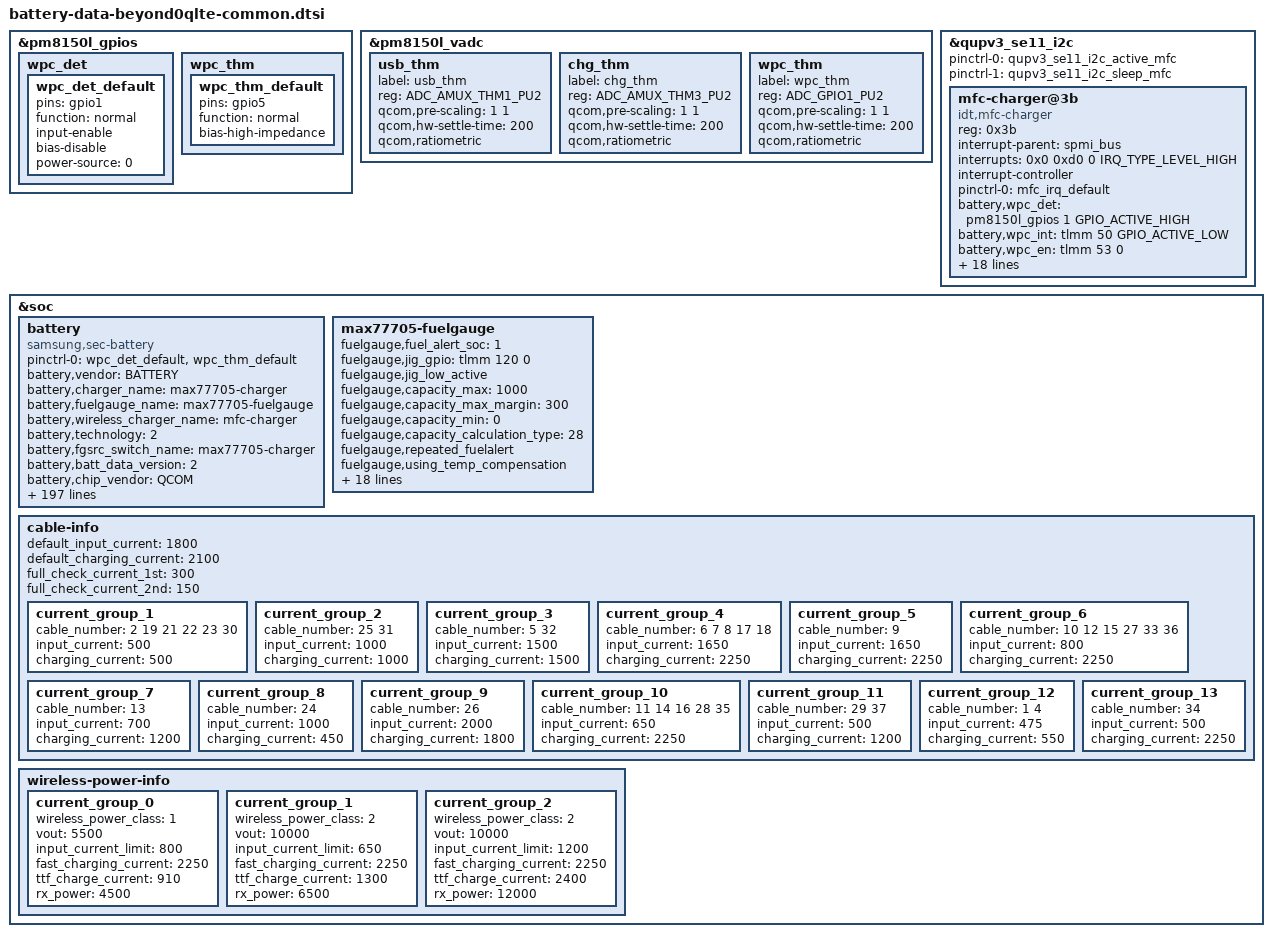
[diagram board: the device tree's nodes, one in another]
/* Copyright (c) 2014, The Linux Foundation. All rights reserved.
 *
 * This program is free software; you can redistribute it and/or modify
 * it under the terms of the GNU General Public License version 2 and
 * only version 2 as published by the Free Software Foundation.
 *
 * This program is distributed in the hope that it will be useful,
 * but WITHOUT ANY WARRANTY; without even the implied warranty of
 * MERCHANTABILITY or FITNESS FOR A PARTICULAR PURPOSE.  See the
 * GNU General Public License for more details.
 */

&pm8150l_gpios {
	wpc_det { /* WPC_DET */
		wpc_det_default: wpc_det_default {
			pins = "gpio1";
			function = "normal";
			input-enable;
			bias-disable;
			power-source = <0>;
		};
	};
	wpc_thm { /* GPIO_05 */
		wpc_thm_default: wpc_thm_default {
			pins = "gpio5";
			function = "normal";
			bias-high-impedance;
		};
	};
};

&pm8150l_vadc {
	usb_thm { /* AMUX_1 */
		label = "usb_thm";
		reg = <ADC_AMUX_THM1_PU2>;
		qcom,pre-scaling = <1 1>;
		qcom,hw-settle-time = <200>;
		qcom,ratiometric;
	};
	chg_thm { /* AMUX_3 */
		label = "chg_thm";
		reg = <ADC_AMUX_THM3_PU2>;
		qcom,pre-scaling = <1 1>;
		qcom,hw-settle-time = <200>;
		qcom,ratiometric;
	};
	wpc_thm { /* GPIO_05 */
		label = "wpc_thm";
		reg = <ADC_GPIO1_PU2>;
		qcom,pre-scaling = <1 1>;
		qcom,hw-settle-time = <200>;
		qcom,ratiometric;
	};
};

&qupv3_se11_i2c {
	status = "ok";

	pinctrl-0 = <&qupv3_se11_i2c_active_mfc>;
	pinctrl-1 = <&qupv3_se11_i2c_sleep_mfc>;

	mfc-charger@3b {
		compatible = "idt,mfc-charger";
		reg = <0x3b>;
		status = "okay";

		interrupt-parent = <&spmi_bus>;
		interrupts = <0x0 0xd0 0 IRQ_TYPE_LEVEL_HIGH>;
		interrupt-names = "default";
		interrupt-controller;
		pinctrl-names = "default";
		pinctrl-0 = <&mfc_irq_default>;
		battery,wpc_det = <&pm8150l_gpios 1 GPIO_ACTIVE_HIGH>; /* WPC_DET */
		battery,wpc_int = <&tlmm 50 GPIO_ACTIVE_LOW>; /* MFC_AP_INT */
		battery,wpc_en = <&tlmm 53 0>; /* WPC_EN */
		battery,mst_en = <&tlmm 11 0>; /* MST_EN */
		battery,mst_pwr_en = <&tlmm 60 0>; /* MST_PWR_EN */

		battery,charger_name = "max77705-charger";
		battery,fuelgauge_name = "max77705-fuelgauge";
		battery,wireless_charger_name = "mfc-charger";
		battery,fod_data = <150 57 142 48 150 33 150 27 165 237 156 13>;
		battery,fod_data_cv = <150 87 142 78 150 63 150 57 165 12 156 43>;
		battery,fod_hero_5v_data = <150 (-27) 142 (-37) 150 (-53) 150 (-53) 165 160 156 (-61)>;
		battery,wc_cover_rpp = <0x44>;
		battery,oc_fod1 = <1100>;
		battery,tx_gear_min_op_freq_delay = <4000>;
		battery,phone_fod_threshold = <0x3b>;		
		battery,wireless20_vout_list = <8>; /* WIRELESS_VOUT_10V*/
		battery,wireless20_vrect_list = <10>; /* MFC_AFC_CONF_12V_TX*/
		battery,wireless20_max_power_list = <2>; /* SEC_WIRELESS_RX_POWER_12W*/
	};
};

&soc {
	battery {
		status = "okay";
		compatible = "samsung,sec-battery";
		pinctrl-names = "default";
		pinctrl-0 = <&wpc_det_default &wpc_thm_default>;
		battery,vendor = "BATTERY";
		battery,charger_name = "max77705-charger";
		battery,fuelgauge_name = "max77705-fuelgauge";
		battery,wireless_charger_name = "mfc-charger";
		battery,technology = <2>; /* POWER_SUPPLY_TECHNOLOGY_LION */
		battery,fgsrc_switch_name = "max77705-charger"; /* Fuelgauge voltage source */

		battery,batt_data_version = <2>;

		battery,chip_vendor = "QCOM";
		battery,temp_adc_type = <1>; /* SEC_BATTERY_ADC_TYPE_AP */

		battery,temp_check_type = <1>; /* SEC_BATTERY_TEMP_CHECK_ADC */
		battery,usb_temp_check_type = <1>;
		battery,chg_temp_check_type = <1>;
		battery,wpc_temp_check_type = <1>;

		battery,thermal_source = <2>; /* SEC_BATTERY_THERMAL_SOURCE_ADC */
		battery,usb_thermal_source = <2>; /* SEC_BATTERY_THERMAL_SOURCE_ADC */
		battery,chg_thermal_source = <2>; /* SEC_BATTERY_THERMAL_SOURCE_ADC */
		battery,wpc_thermal_source = <2>; /* SEC_BATTERY_THERMAL_SOURCE_ADC */

		battery,polling_time = <10 30 30 30 3600>;

		battery,temp_table_adc = <146452 171453 197469 227486 264402
						306877 355795 413408 478330 553546
						633390 725216 825583 931271 1041716
						1153113 1259536 1360163 1455557 1535856
						1605990 1667106 1717884>;
		battery,temp_table_data = <900 850 800 750 700
						650 600 550 500 450
						400 350 300 250 200
						150 100 50 0 (-50)
						(-100) (-150) (-200)>;

		battery,usb_temp_table_adc = <133671 155600 181725 212391 250323
						291349 341327 399610 465765 541803
						622923 716046 818382 925972 1037586
						1150691 1258780 1360056 1456920 1537435
						1607871 1669398 1720523>;
		battery,usb_temp_table_data = <900 850 800 750 700
						650 600 550 500 450
						400 350 300 250 200
						150 100 50 0 (-50)
						(-100) (-150) (-200)>;

		battery,chg_temp_table_adc = <118901 149458 175778 205968 242754
						284364 334601 392538 458022 532655
						614403 706725 806465 913170 1022187
						1133801 1238927 1338732 1431833 1511202
						1579173 1640484 1699264>;
		battery,chg_temp_table_data = <900 850 800 750 700
						650 600 550 500 450
						400 350 300 250 200
						150 100 50 0 (-50)
						(-100) (-150) (-200)>;

		battery,wpc_temp_table_adc = <146452 171453 197469 227486 264402
						306877 355795 413408 478330 553546
						633390 725216 825583 931271 1041716
						1153113 1259536 1360163 1455557 1535856
						1605990 1667106 1717884>;
		battery,wpc_temp_table_data = <900 850 800 750 700
						650 600 550 500 450
						400 350 300 250 200
						150 100 50 0 (-50)
						(-100) (-150) (-200)>;

		battery,wireless_cc_cv = <85>;
		battery,wpc_det = <&pm8150l_gpios 1 GPIO_ACTIVE_HIGH>; /* WPC_DET */
		battery,wpc_en = <&tlmm 53 0>; /* WPC_EN */
		battery,mst_pwr_en = <&tlmm 60 0>; /* MST_PWR_EN */
		battery,adc_check_count = <5>;

		battery,cable_check_type = <4>; /* SEC_BATTERY_CABLE_CHECK_PSY */
		battery,cable_source_type = <1>; /* SEC_BATTERY_CABLE_SOURCE_EXTERNAL */
		battery,polling_type = <1>; /* SEC_BATTERY_MONITOR_ALARM */
		battery,monitor_initial_count = <0>;

		battery,battery_check_type = <0>; /* SEC_BATTERY_CHECK_NONE */
		battery,check_count = <0>;
		battery,check_adc_max = <1440>;
		battery,check_adc_min = <0>;

		battery,ovp_uvlo_check_type = <3>; /* SEC_BATTERY_OVP_UVLO_CHGPOLLING */

		battery,temp_check_count = <1>;
		battery,temp_highlimit_threshold_event = <700>;
		battery,temp_highlimit_recovery_event = <680>;
		battery,temp_high_threshold_event = <500>;
		battery,temp_high_recovery_event = <480>;
		battery,temp_low_threshold_event = <0>;
		battery,temp_low_recovery_event = <20>;
		battery,temp_highlimit_threshold_normal = <700>;
		battery,temp_highlimit_recovery_normal = <680>;
		battery,temp_high_threshold_normal = <500>;
		battery,temp_high_recovery_normal = <480>;
		battery,temp_low_threshold_normal = <0>;
		battery,temp_low_recovery_normal = <20>;
		battery,temp_highlimit_threshold_lpm = <700>;
		battery,temp_highlimit_recovery_lpm = <680>;
		battery,temp_high_threshold_lpm = <500>;
		battery,temp_high_recovery_lpm = <480>;
		battery,temp_low_threshold_lpm = <0>;
		battery,temp_low_recovery_lpm = <20>;
		battery,wpc_high_threshold_normal = <450>;
		battery,wpc_high_recovery_normal = <430>;
		battery,wpc_low_threshold_normal = <0>;
		battery,wpc_low_recovery_normal = <20>;
		battery,tx_high_threshold = <450>;
		battery,tx_high_recovery = <400>;
		battery,tx_low_threshold = <0>;
		battery,tx_low_recovery = <50>;
		battery,full_check_type = <7>; /* SEC_BATTERY_FULLCHARGED_CHGPSY */
		battery,full_check_type_2nd = <7>; /* SEC_BATTERY_FULLCHARGED_CHGPSY */
		battery,full_check_count = <1>;
		battery,chg_gpio_full_check = <0>;
		battery,chg_polarity_full_check = <1>;

		battery,chg_high_temp = <460>;
		battery,chg_high_temp_recovery = <440>;
		battery,chg_input_limit_current = <1000>;
		battery,chg_charging_limit_current = <1250>;

		battery,wpc_temp_control_source = <1>; /* TEMP_CONTROL_SOURCE_BAT_THM = WPC_THM */
		battery,wpc_high_temp = <380>;
		battery,wpc_high_temp_recovery = <360>;
		battery,wpc_input_limit_current = <600>;
		battery,wpc_charging_limit_current = <1000>;
		battery,wpc_temp_lcd_on_control_source = <1>; /* TEMP_CONTROL_SOURCE_BAT_THM = WPC_THM */
		battery,wpc_lcd_on_high_temp = <380>;
		battery,wpc_lcd_on_high_temp_rec = <360>;
		battery,wpc_lcd_on_input_limit_current = <450>;

		battery,wpc_store_high_temp = <360>;
		battery,wpc_store_high_temp_recovery = <340>;
		battery,wpc_store_charging_limit_current = <400>;
		battery,wpc_store_lcd_on_high_temp = <360>;
		battery,wpc_store_lcd_on_high_temp_rec = <300>;
		battery,wpc_store_lcd_on_charging_limit_current = <400>;

		battery,sleep_mode_limit_current = <800>;
		battery,wc_full_input_limit_current = <100>;

		battery,mix_high_temp = <420>;
		battery,mix_high_chg_temp = <500>;
		battery,mix_high_temp_recovery = <390>;

		/* SEC_BATTERY_FULL_CONDITION_NOTIMEFULL | SEC_BATTERY_FULL_CONDITION_VCELL */
		battery,full_condition_type = <9>;
		battery,full_condition_soc = <93>;
		battery,full_condition_vcell = <4250>;

		battery,recharge_check_count = <1>;
		battery,recharge_condition_type = <4>; /* SEC_BATTERY_RECHARGE_CONDITION_VCELL */
		battery,recharge_condition_soc = <98>;
		battery,recharge_condition_vcell = <4280>;

		battery,charging_total_time = <14400>;
		battery,hv_charging_total_time = <10800>;
		battery,normal_charging_total_time = <18000>;
		battery,usb_charging_total_time = <36000>;
		battery,recharging_total_time = <5400>;
		battery,charging_reset_time = <0>;

		battery,chg_float_voltage = <4350>;
		battery,chg_ocp_current = <5600>;

		battery,pre_afc_work_delay = <2000>;
		battery,pre_wc_afc_work_delay = <4000>;
		battery,pre_afc_input_current = <500>;
		battery,pre_wc_afc_input_current = <500>;
		battery,prepare_ta_delay = <0>; /* msec */

		battery,swelling_high_temp_block = <410>;
		battery,swelling_high_temp_recov = <390>;
		battery,swelling_low_temp_block_1st = <150>;
		battery,swelling_low_temp_recov_1st = <170>;
		battery,swelling_low_temp_block_2nd = <50>;
		battery,swelling_low_temp_recov_2nd = <70>;

		battery,swelling_low_temp_current = <700>;	/* 0.24C */
		battery,swelling_low_temp_current_2nd = <300>;	/* 0.1C */
		battery,swelling_low_temp_topoff = <150>;	/* 0.05C */
		battery,swelling_high_temp_current = <1050>;	/* 0.36C */
		battery,swelling_high_temp_topoff = <150>;	/* 0.05C */
		battery,swelling_wc_high_temp_current = <700>;	/* 0.24C */
		battery,swelling_wc_low_temp_current = <700>;	/* 0.24C */
		battery,swelling_wc_low_temp_current_2nd = <300>;	/* 0.1C */

		battery,swelling_drop_float_voltage = <4150>;
		battery,swelling_high_rechg_voltage = <4000>;
		battery,swelling_low_rechg_thr = <150>;

		battery,siop_input_limit_current = <1200>;
		battery,siop_charging_limit_current = <1000>;
		battery,siop_hv_input_limit_current = <700>;
		battery,siop_hv_input_limit_current_2nd = <550>;
		battery,siop_hv_charging_limit_current = <1000>;

		battery,siop_wireless_input_limit_current = <600>;
		battery,siop_wireless_charging_limit_current = <700>;
		battery,siop_hv_wireless_input_limit_current = <600>;
		battery,siop_hv_wireless_charging_limit_current = <700>;
		battery,siop_store_hv_wireless_input_limit_current = <450>;

		battery,wireless_otg_input_current = <900>;

		battery,ttf_hv_charge_current = <2400>;
		battery,ttf_hv_12v_wireless_charge_current = <2400>;
		battery,ttf_hv_wireless_charge_current = <1300>;
		battery,ttf_wireless_charge_current = <910>;

		battery,rp_current_rp1 = <500>;
		battery,rp_current_rp2 = <1500>;
		battery,rp_current_rp3 = <3000>;
		battery,rp_current_rdu_rp3 = <2100>;
		battery,rp_current_abnormal_rp3 = <1800>;

		battery,pd_charging_charge_power = <15000>;
		battery,max_charging_current = <2250>;

		/* cycle, chg_float_voltage, recharge_condition_vcell, full_condition_vcell, full_condition_soc, step charging condition */
		battery,age_data = <0 4350 4280 4250 93 35
				300 4330 4260 4230 92 35
				400 4310 4240 4210 91 35
				700 4290 4220 4190 90 35
				1000 4240 4170 4140 89 35>;

		battery,health_condition = <
				/* CYCLE ASOC */
				900 75	/* GOOD */
				1200 65 /* NORMAL */
				1500 55 /* AGED */
				>;

		/* step charging option */
		battery,step_charging_type = <0x3E>;
		battery,step_charging_charge_power = <12000>;
		battery,step_charging_condition = <35 100>;
		battery,step_charging_condition_curr = <2250 2250>;
		battery,step_charging_current = <3100 2250>;
		battery,step_charging_float_voltage = <4150 4350>;

		battery,max_input_voltage = <9000>; /* mV */
		battery,max_input_current = <3000>;  /* mA */

		battery,enable_sysovlo_irq;
		battery,enable_noise_wa;

		battery,standard_curr = <2250>;
		battery,expired_time = <10800>;
		battery,recharging_expired_time = <5400>;

		battery,battery_full_capacity = <3000>;
		battery,cisd_max_voltage_thr = <4400>; /* batttery ovp dettection voltage */
		battery,cisd_alg_index = <8>;
		battery,ignore_cisd_index = <0 0>;
		battery,ignore_cisd_index_d = <0 80>; /* Do not use AFC_FAIL_PER_DAY to DROP_VALUE_PER_DAY */ 

		battery,tx_stop_capacity = <30>;
		battery,tx_minduty_default = <20>;
		battery,tx_minduty_5V = <50>;

		battery,tx_uno_iout = <1500>;
		battery,tx_mfc_iout_gear = <1500>;
		battery,tx_mfc_iout_phone = <1100>;
		battery,tx_mfc_iout_phone_5v = <300>;
		battery,tx_mfc_iout_lcd_on = <900>;

		io-channels = <&pm8150l_vadc ADC_GPIO1_PU2>, <&pm8150l_vadc ADC_AMUX_THM3_PU2>, <&pm8150l_vadc ADC_GPIO1_PU2>, <&pm8150l_vadc ADC_AMUX_THM1_PU2>;
		io-channel-names = "adc-temp", "adc-chg-temp", "adc-wpc-temp", "adc-usb-temp";
	};

	max77705-fuelgauge {
		status = "okay";
		fuelgauge,fuel_alert_soc = <1>;
		fuelgauge,jig_gpio = <&tlmm 120 0>; /* IFC_SENSE_INT_AP */
		fuelgauge,jig_low_active;
		fuelgauge,capacity_max = <1000>;
		fuelgauge,capacity_max_margin = <300>;
		fuelgauge,capacity_min = <0>;
		fuelgauge,capacity_calculation_type = <28>;
		fuelgauge,repeated_fuelalert;
		fuelgauge,using_temp_compensation;
		fuelgauge,low_temp_limit = <100>;
		fuelgauge,using_hw_vempty;
		fuelgauge,v_empty = <0xA7E2>; /* Empty: 3350mV, Recover: 3920mV */
		fuelgauge,v_empty_origin = <0x7D54>; /* Empty: 2500mV, Recover: 3360mV */
		fuelgauge,sw_v_empty_voltage = <3200>;
		fuelgauge,sw_v_empty_voltage_cisd = <3100>;
		fuelgauge,sw_v_empty_recover_voltage = <3480>;
		fuelgauge,qrtable20 = <0x1500>;
		fuelgauge,qrtable30 = <0x1280>;
		fuelgauge,fg_resistor = <2>;
		fuelgauge,capacity = <0x0BB8>; /*capacity = fullcapnom = DesignCap*/
		fuelgauge,fg_reset_wa_data = <0x0BB8 0x3200 0x02EE 0x003F 0x1F20>; /* fullcapnom(=capacity), dPacc, dQacc,  rcomp0, tempco */
		fuelgauge,discharge_temp_threshold = <600>;
		fuelgauge,discharge_volt_threshold = <4200>;
		fuelgauge,ttf_capacity = <2700>;
		fuelgauge,cv_data = <
			2220	722 	2884
			2108	742 	2793
			1935	767 	2669
			1815	784 	2580
			1703	800 	2489
			1580	815 	2397
			1456	834 	2275
			1325	857 	2153
			1164	870 	2001
			1062	884 	1879
			939	902 	1696
			810	919 	1502
			737	931 	1351
			664	941 	1202
			595	953 	1023
			505	962 	842
			440	972 	629
			343	984 	326
			302	990 	143
			276	1000 	0
			>;
	};

/* sec_battery_cable
 *   0	UNKNOWN,
 *   1	NONE,
 *   2	PREPARE_TA,
 *   3	TA,
 *   4	USB,
 *   5	USB_CDP,
 *   6	9V_TA,
 *   7	9V_ERR,
 *   8	9V_UNKNOWN,
 *   9	12V_TA,
 *  10	WIRELESS,
 *  11	HV_WIRELESS,
 *  12	PMA_WIRELESS,
 *  13	WIRELESS_PACK,
 *  14	CABLE_WIRELESS_HV_PACK,
 *  15	WIRELESS_STAND,
 *  16	WIRELESS_HV_STAND,
 *  17	QC20,
 *  18	QC30,
 *  19	PDIC,
 *  20	UARTOFF,
 *  21	OTG,
 *  22	LAN_HUB,
 *  23	POWER_SHARING,
 *  24	HMT_CONNECTED,
 *  25	HMT_CHARGE,
 *  26	HV_TA_CHG_LIMIT,
 *  27	WIRELESS_VEHICLE,
 *  28	WIRELESS_HV_VEHICLE,
 *  29	PREPARE_WIRELESS_HV,
 *  30  TIMEOUT,
 *  31  SMART_OTG,
 *  32  SMART_NOTG,
 *  33  WIRELESS_TX,
 *  34	HV_WIRELESS_20,
 *  35	HV_WIRELESS_20_LIMIT,
 *  36	WIRELESS_FAKE,
 *  37  PREPARE_WIRELESS_20,
 *  38	CABLE_PDIC_APDO,
 *  39	CABLE_MAX,
 */
	cable-info {
		default_input_current = <1800>;
		default_charging_current = <2100>;
		full_check_current_1st = <300>;
		full_check_current_2nd = <150>;

		current_group_1 {
			cable_number = <2 19 21 22 23 30>;
			input_current = <500>;
			charging_current = <500>;
		};
		current_group_2 {
			cable_number = <25 31>;
			input_current = <1000>;
			charging_current = <1000>;
		};
		current_group_3 {
			cable_number = <5 32>;
			input_current = <1500>;
			charging_current = <1500>;
		};
		current_group_4 {
			cable_number = <6 7 8 17 18>;
			input_current = <1650>;
			charging_current = <2250>;
		};
		current_group_5 {
			cable_number = <9>;
			input_current = <1650>;
			charging_current = <2250>;
		};
		current_group_6 {
			cable_number = <10 12 15 27 33 36>;
			input_current = <800>;
			charging_current = <2250>;
		};
		current_group_7 {
			cable_number = <13>;
			input_current = <700>;
			charging_current = <1200>;
		};
		current_group_8 {
			cable_number = <24>;
			input_current = <1000>;
			charging_current = <450>;
		};
		current_group_9 {
			cable_number = <26>;
			input_current = <2000>;
			charging_current = <1800>;
		};
		current_group_10 {
			cable_number = <11 14 16 28 35>;
			input_current = <650>;
			charging_current = <2250>;
		};
		current_group_11 {
			cable_number = <29 37>;
			input_current = <500>;
			charging_current = <1200>;
		};
		current_group_12 {
			cable_number = <1 4>;
			input_current = <475>;
			charging_current = <550>;
		};
		current_group_13 {
			cable_number = <34>;
			input_current = <500>;
			charging_current = <2250>;
		};
	};
	wireless-power-info {
		current_group_0 {
			wireless_power_class = <1>;
			vout = <5500>;
			input_current_limit = <800>;
			fast_charging_current = <2250>;
			ttf_charge_current = <910>;
			rx_power = <4500>;
		};
		current_group_1 {
			wireless_power_class = <2>;
			vout = <10000>;
			input_current_limit = <650>;
			fast_charging_current = <2250>;
			ttf_charge_current = <1300>;
			rx_power = <6500>;
		};
		current_group_2 {
			wireless_power_class = <2>;
			vout = <10000>;
			input_current_limit = <1200>;
			fast_charging_current = <2250>;
			ttf_charge_current = <2400>;
			rx_power = <12000>;
		};
	};
};
